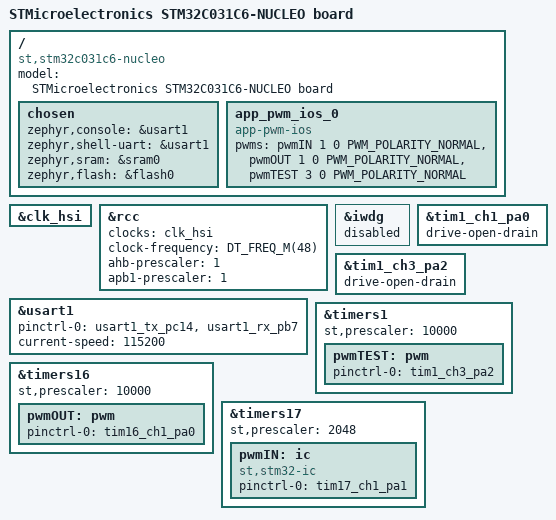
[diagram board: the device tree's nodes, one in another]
/*
 * Copyright (c) 2023 Benjamin Björnsson <benjamin.bjornsson@gmail.com>
 *
 * SPDX-License-Identifier: Apache-2.0
 */

/dts-v1/;
#include <st/c0/stm32c031X6.dtsi>
#include <st/c0/stm32c031c(4-6)tx-pinctrl.dtsi>

/ {
	model = "STMicroelectronics STM32C031C6-NUCLEO board";
	compatible = "st,stm32c031c6-nucleo";

	chosen {
		zephyr,console = &usart1;
		zephyr,shell-uart = &usart1;
		zephyr,sram = &sram0;
		zephyr,flash = &flash0;
	};

	app_pwm_ios_0 {
		compatible = "app-pwm-ios";
		pwms = <&pwmIN 1 0 PWM_POLARITY_NORMAL>, //IN
			<&pwmOUT 1 0 PWM_POLARITY_NORMAL>, //OUT
			<&pwmTEST 3 0 PWM_POLARITY_NORMAL>; //TEST
	};
};

&clk_hsi {
	status = "okay";
};

&rcc {
	clocks = <&clk_hsi>;
	clock-frequency = <DT_FREQ_M(48)>;
	ahb-prescaler = <1>;
	apb1-prescaler = <1>;
};

&usart1 {
	status = "okay";
	pinctrl-0 = <&usart1_tx_pc14 &usart1_rx_pb7>;
	pinctrl-names = "default";
	current-speed = <115200>;
};

&iwdg {
	status = "disabled";
};

&tim1_ch1_pa0 {
	drive-open-drain;
};

&tim1_ch3_pa2 {
	drive-open-drain;
};

&timers1 {
	st,prescaler = <10000>;
	status = "okay";

	/* TEST */
	pwmTEST: pwm {
		status = "okay";
		pinctrl-0 = <&tim1_ch3_pa2>;
		pinctrl-names = "default";
	};
};

&timers16 {
	st,prescaler = <10000>;
	status = "okay";

	/* IN_MOTOR on schematics */
	pwmOUT: pwm {
		status = "okay";
		pinctrl-0 = <&tim16_ch1_pa0>;
		pinctrl-names = "default";
	};
};

&timers17 {
	st,prescaler = <2048>;
	status = "okay";
	
	/* OUT_CTRL on schematics */
	pwmIN: ic {
		compatible = "st,stm32-ic";
		status = "okay";
		#pwm-cells = <3>;
		pinctrl-0 = <&tim17_ch1_pa1>;
		pinctrl-names = "default";
	};
};

